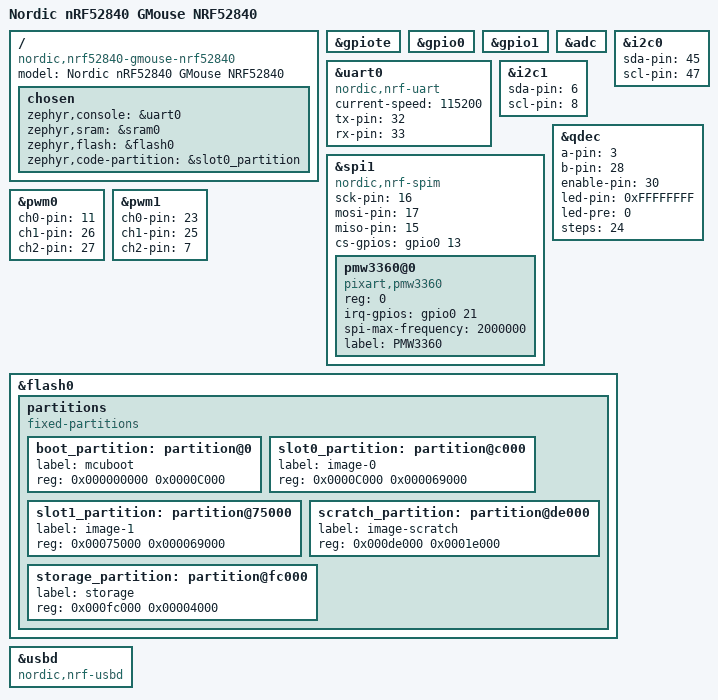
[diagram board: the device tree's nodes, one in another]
/*
 * Copyright (c) 2018 Nordic Semiconductor ASA
 *
 * SPDX-License-Identifier: LicenseRef-BSD-5-Clause-Nordic
 */

/dts-v1/;
#include <nordic/nrf52840_qiaa.dtsi>

/ {
	model = "Nordic nRF52840 GMouse NRF52840";
	compatible = "nordic,nrf52840-gmouse-nrf52840";

	chosen {
		zephyr,console = &uart0;
		zephyr,sram = &sram0;
		zephyr,flash = &flash0;
		zephyr,code-partition = &slot0_partition;
	};
};

&gpiote {
	status = "okay";
};

&gpio0 {
	status = "okay";
};

&gpio1 {
	status = "okay";
};

&adc {
	status = "okay";
};

&uart0 {
	status = "okay";
	compatible = "nordic,nrf-uart";
	current-speed = <115200>;
	tx-pin = <32>;
	rx-pin = <33>;
};

&i2c0 {
	status = "okay";
	sda-pin = <45>;
	scl-pin = <47>;
};

&i2c1 {
	status = "okay";
	sda-pin = <6>;
	scl-pin = <8>;
};

&spi1 {
	compatible = "nordic,nrf-spim";
	status = "okay";
	sck-pin = <16>;
	mosi-pin = <17>;
	miso-pin = <15>;
	cs-gpios = <&gpio0 13 0>;

	pmw3360@0 {
		compatible = "pixart,pmw3360";
		reg = <0>;
		irq-gpios = <&gpio0 21 0>;
		spi-max-frequency = <2000000>;
		label = "PMW3360";
	};
};

&qdec {
	status = "okay";
	a-pin = <3>;
	b-pin = <28>;
	enable-pin = <30>;
	led-pin = <0xFFFFFFFF>;
	led-pre = <0>;
	steps = <24>;
};

&pwm0 {
	status = "okay";
	ch0-pin = <11>;
	ch1-pin = <26>;
	ch2-pin = <27>;
};

&pwm1 {
	status = "okay";
	ch0-pin = <23>;
	ch1-pin = <25>;
	ch2-pin = <7>;
};

&flash0 {
	/*
	 * For more information, see:
	 * http://docs.zephyrproject.org/devices/dts/flash_partitions.html
	 */
	partitions {
		compatible = "fixed-partitions";
		#address-cells = <1>;
		#size-cells = <1>;

		boot_partition: partition@0 {
			label = "mcuboot";
			reg = <0x000000000 0x0000C000>;
		};
		slot0_partition: partition@c000 {
			label = "image-0";
			reg = <0x0000C000 0x000069000>;
		};
		slot1_partition: partition@75000 {
			label = "image-1";
			reg = <0x00075000 0x000069000>;
		};
		scratch_partition: partition@de000 {
			label = "image-scratch";
			reg = <0x000de000 0x0001e000>;
		};

		storage_partition: partition@fc000 {
			label = "storage";
			reg = <0x000fc000 0x00004000>;
		};
	};
};

&usbd {
	compatible = "nordic,nrf-usbd";
	status = "okay";
};
